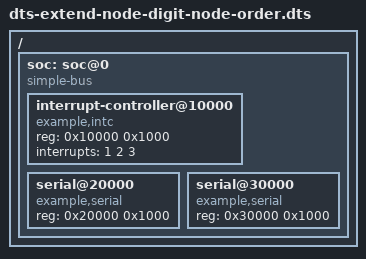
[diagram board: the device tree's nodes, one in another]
// SPDX-License-Identifier: GPL-2.0-only OR BSD-2-Clause
/dts-v1/;

/ {
	#address-cells = <1>;
	#size-cells = <1>;

	soc: soc@0 {
		compatible = "simple-bus";
		ranges = <0 0 0 0xc0000000>;

		#address-cells = <1>;
		#size-cells = <1>;
	};
};

&soc {
	interrupt-controller@10000 {
		compatible = "example,intc";
		reg = <0x10000 0x1000>;
		interrupts = <1 2 3>;
	};

	serial@20000 {
		compatible = "example,serial";
		reg = <0x20000 0x1000>;
	};

	serial@30000 {
		compatible = "example,serial";
		reg = <0x30000 0x1000>;
	};
};
